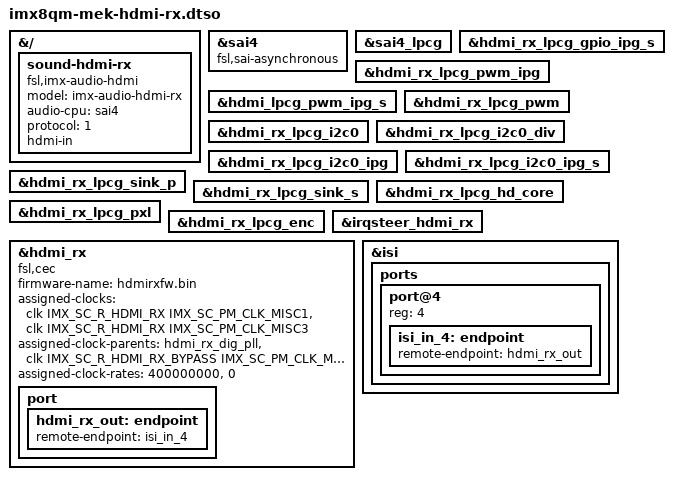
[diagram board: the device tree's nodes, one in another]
// SPDX-License-Identifier: (GPL-2.0+ OR MIT)
/*
 * Copyright 2024 NXP
 */
/dts-v1/;
/plugin/;

#include <dt-bindings/firmware/imx/rsrc.h>

&{/} {
	sound-hdmi-rx {
		compatible = "fsl,imx-audio-hdmi";
		model = "imx-audio-hdmi-rx";
		audio-cpu = <&sai4>;
		protocol = <1>;
		hdmi-in;
	};
};

&sai4 {
	fsl,sai-asynchronous;
	status = "okay";
};

&sai4_lpcg {
	status = "okay";
};

&hdmi_rx_lpcg_gpio_ipg_s {
	status = "okay";
};

&hdmi_rx_lpcg_pwm_ipg {
	status = "okay";
};

&hdmi_lpcg_pwm_ipg_s {
	status = "okay";
};

&hdmi_rx_lpcg_pwm {
	status = "okay";
};

&hdmi_rx_lpcg_i2c0 {
	status = "okay";
};

&hdmi_rx_lpcg_i2c0_div {
	status = "okay";
};

&hdmi_rx_lpcg_i2c0_ipg {
	status = "okay";
};

&hdmi_rx_lpcg_i2c0_ipg_s {
	status = "okay";
};

&hdmi_rx_lpcg_sink_p {
	status = "okay";
};

&hdmi_rx_lpcg_sink_s {
	status = "okay";
};

&hdmi_rx_lpcg_hd_core {
	status = "okay";
};

&hdmi_rx_lpcg_pxl {
	status = "okay";
};

&hdmi_rx_lpcg_enc {
	status = "okay";
};

&irqsteer_hdmi_rx {
	status = "okay";
};

&hdmi_rx {
	fsl,cec;
	firmware-name = "hdmirxfw.bin";
	assigned-clocks = <&clk IMX_SC_R_HDMI_RX IMX_SC_PM_CLK_MISC1>,
			  <&clk IMX_SC_R_HDMI_RX IMX_SC_PM_CLK_MISC3>;
	assigned-clock-parents = <&hdmi_rx_dig_pll>,
				 <&clk IMX_SC_R_HDMI_RX_BYPASS IMX_SC_PM_CLK_MISC2>;
	assigned-clock-rates = <400000000>, <0>;
	status = "okay";

	port {
		hdmi_rx_out: endpoint {
			remote-endpoint = <&isi_in_4>;
		};
	};
};

&isi {
	status = "okay";

	ports {
		#address-cells = <1>;
		#size-cells = <0>;

		port@4 {
			reg = <4>;

			isi_in_4: endpoint {
				remote-endpoint = <&hdmi_rx_out>;
			};
		};
	};
};
